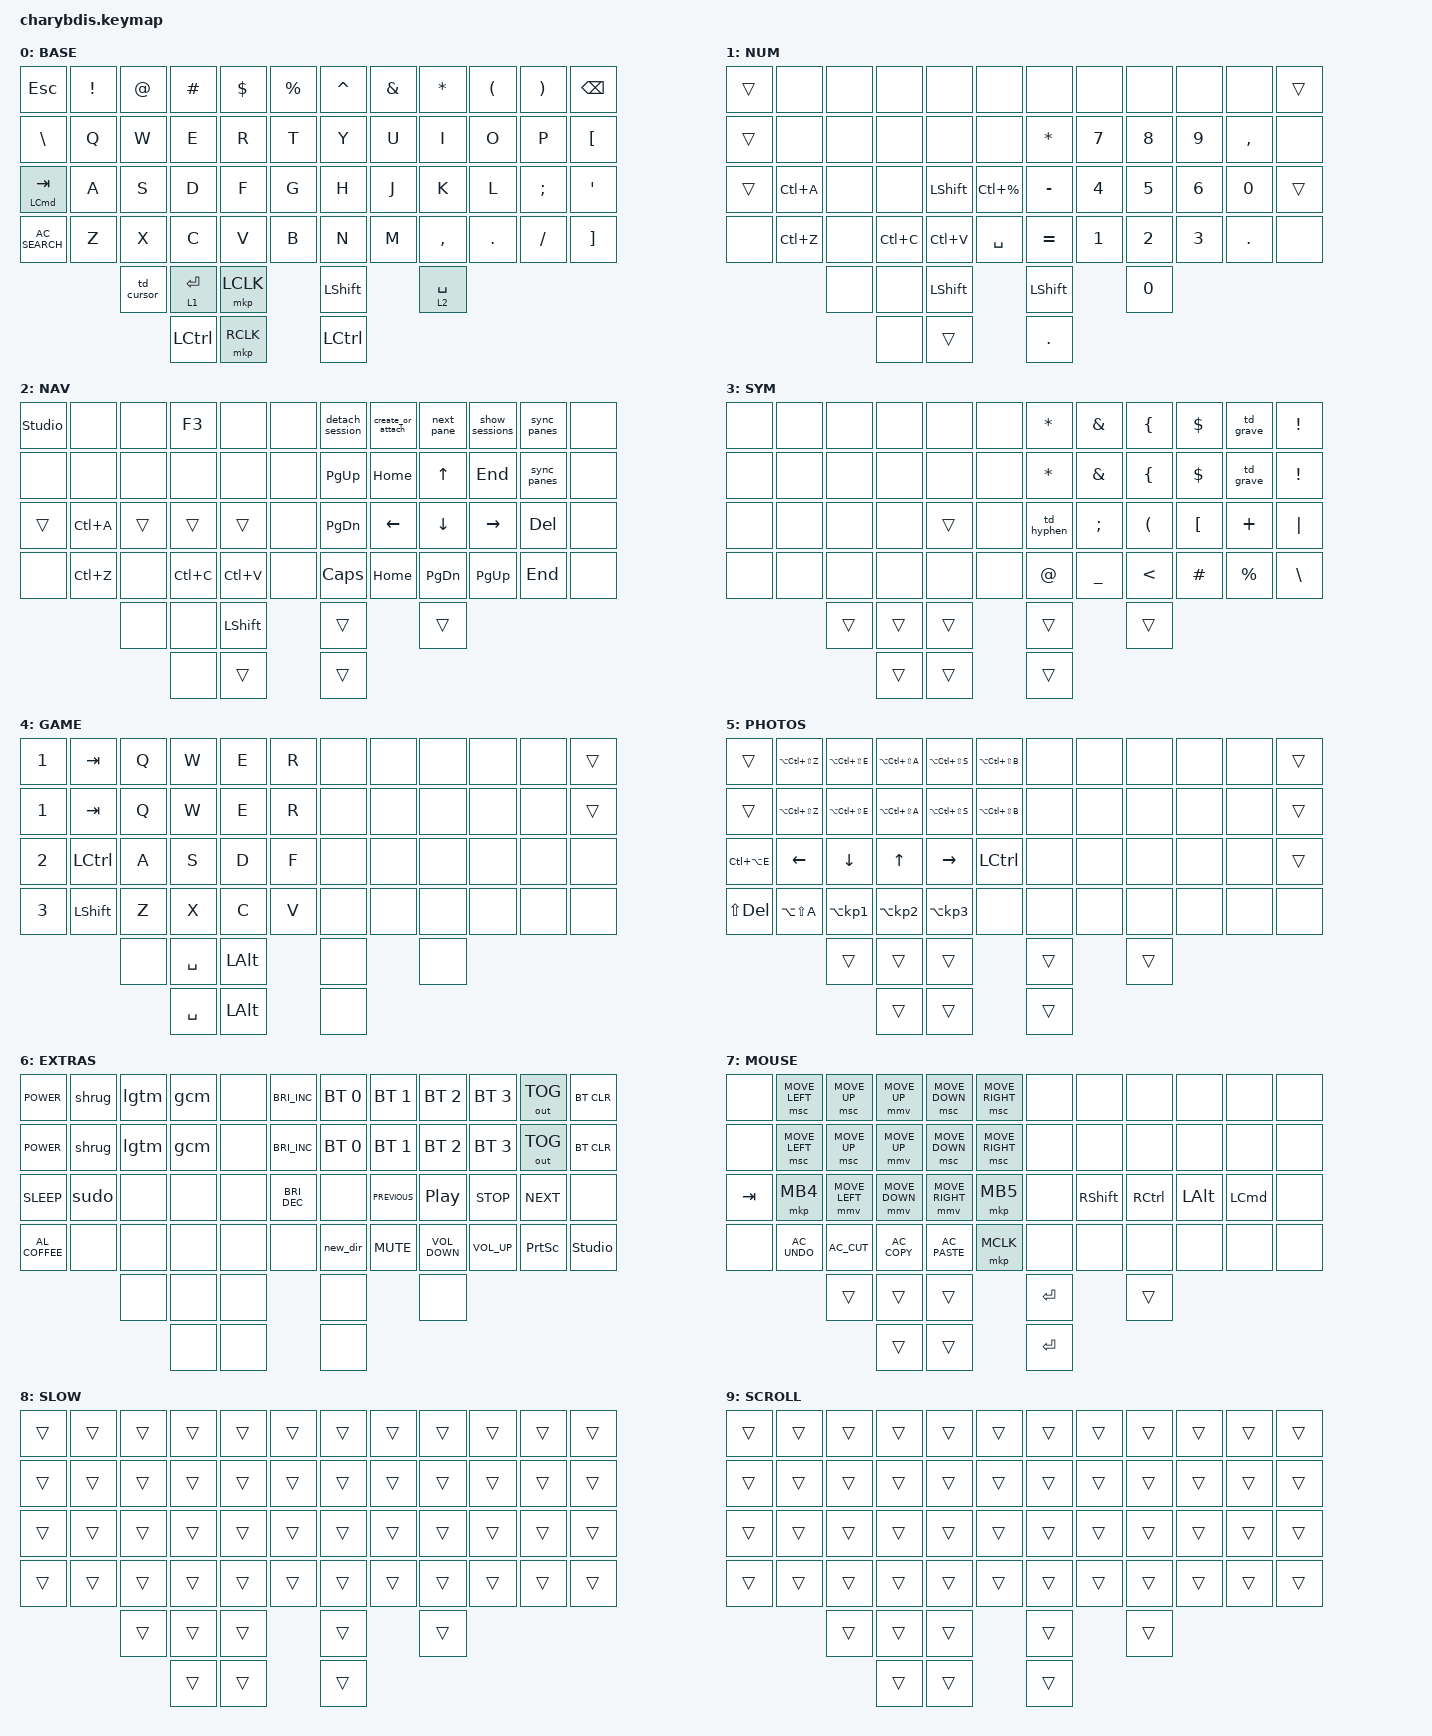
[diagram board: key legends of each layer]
#include <behaviors.dtsi>
#include <dt-bindings/zmk/bt.h>
#include <dt-bindings/zmk/keys.h>
#include <dt-bindings/zmk/mouse.h>
#include <dt-bindings/zmk/outputs.h>
#include <behaviors/mouse_keys.dtsi>
#include <dt-bindings/zmk/ext_power.h>
#include "macros.dtsi"
#include "behaviors.dtsi"
#include "combos.dtsi"

/ {
    /* input config for mouse move mode */
    trackball_listener {
        compatible = "zmk,input-behavior-listener";
        device = <&vtrackball>;
        layers = <0 2 7>;
        evt-type = <INPUT_EV_REL>;
        x-input-code = <INPUT_REL_X>;
        y-input-code = <INPUT_REL_Y>;
        scale-multiplier = <4>;
        scale-divisor = <5>;
        // bindings = <&ib_toggle_layer 7>;
    };

    /* input config for snipe mode */
    trackball_snipe_listener {
        compatible = "zmk,input-behavior-listener";   
        device = <&vtrackball>;
        layers = <8>;
        evt-type = <INPUT_EV_REL>;
        x-input-code = <INPUT_REL_X>;
        y-input-code = <INPUT_REL_Y>;
        scale-multiplier = <1>;
        scale-divisor = <2>;
    };

    /* input config for mouse scroll mode */
    trackball_scroll_listener {
        compatible = "zmk,input-behavior-listener";
        device = <&vtrackball>;
        layers = <9>;
        evt-type = <INPUT_EV_REL>;            
        y-input-code = <INPUT_REL_WHEEL>;
        y-invert;
        bindings = <&ib_wheel_scaler 1 8>;
    };

    /* define a resolution down scaler only for INPUT_REL_WHEEL */
    ib_wheel_scaler: ib_wheel_scaler {
        compatible = "zmk,input-behavior-scaler";
        #binding-cells = <2>;
        evt-type = <INPUT_EV_REL>;
        input-code = <INPUT_REL_WHEEL>;
        
    };

    /* adjust cooldown waiting period for mouse key layer after activated */
    ib_toggle_layer: ib_toggle_layer {
        compatible = "zmk,input-behavior-tog-layer";
        #binding-cells = <1>;
        time-to-live-ms = <750>;
    };
// ╭──────┬──────┬──────┬──────┬──────┬──────╮  ╭──────┬──────┬──────┬──────┬──────┬──────╮
//    00     01     02     03    04      05        06     07     08     09     10     11
// ├──────┼──────┼──────┼──────┼──────┼──────┤  ├──────┼──────┼──────┼──────┼──────┼──────┤
//    12     13     14     15    16      17        18     19     20     21     22     23
// ├──────┼──────┼──────┼──────┼──────┼──────┤  ├──────┼──────┼──────┼──────┼──────┼──────┤
//    24     25     26     27    28      29        30     31     32     33     34     35
// ├──────┼──────┼──────┼──────┼──────┼──────┤  ├──────┼──────┼──────┼──────┼──────┼──────┤
//    36     37     38     39    40      41        42     43     44     45     46     47
// ╰──────┴──────┴──────┼──────┼──────┼──────┤  ├──────┼──────┼──────┴──────┴──────┴──────╯
//                         48     49     50        53     54
//                       ──────┼──────┼──────┤  ├──────┼──────┼
//                                51     52        55
//                             ╰──────┴──────╯  ╰──────╯
// #define BASE    0
// #define NUM     1
// #define NAV     2
// #define SYM     3
// #define GAME    4
// #define PHOTOS  5
// #define EXTRAS  6
// #define MOUSE   7
// #define SLOW    8
// #define SCROLL  9

    keymap {
        compatible = "zmk,keymap";
        BASE {
            bindings = <
// ╭────────────────┬──────────────┬─────────────────────────────┬──────────────────────────────────┬──────────────────────┬────────╮  ╭────────────────┬─────────────────────────┬──────────────────────────────────────┬────────────────────────────────────┬────────────────────────┬──────────────╮
    &kp ESC            &kp EXCL        &kp AT                         &kp HASH                         &kp DOLLAR             &kp PERCENT &kp CARET         &kp AMPS                &kp STAR                                &kp LPAR                             &kp RPAR                 &kp BACKSPACE
// ├────────────────┼──────────────┼─────────────────────────────┼──────────────────────────────────┼──────────────────────┼────────┤  ├────────────────┼─────────────────────────┼──────────────────────────────────────┼────────────────────────────────────┼────────────────────────┼──────────────┤
    &kp BACKSLASH      &kp Q           &kp W                          &kp E                              &kp R                  &kp T       &kp Y             &kp U                   &kp I                                   &kp O                                &kp P                    &kp LEFT_BRACKET
// ├────────────────┼──────────────┼─────────────────────────────┼──────────────────────────────────┼──────────────────────┼────────┤  ├────────────────┼─────────────────────────┼──────────────────────────────────────┼────────────────────────────────────┼────────────────────────┼──────────────┤
    &hm_left LCMD TAB  &kp A         &kp S                            &kp D                             &kp F                   &kp G       &kp H             &kp J                   &kp K                                   &kp L                                &kp SEMICOLON            &kp SINGLE_QUOTE
// ├────────────────┼──────────────┼─────────────────────────────┼──────────────────────────────────┼──────────────────────┼────────┤  ├────────────────┼─────────────────────────┼──────────────────────────────────────┼────────────────────────────────────┼────────────────────────┼──────────────┤
    &kp C_AC_SEARCH    &kp Z           &kp X                          &kp C                              &kp V                  &kp B       &kp N             &kp M                   &kp COMMA                               &kp PERIOD                           &kp FSLH                 &kp RIGHT_BRACKET
// ╰────────────────┴──────────────┴─────────────────────────────┼──────────────────────────────────┼──────────────────────┼────────┤  ├────────────────┼─────────────────────────┼──────────────────────────────────────┴────────────────────────────────────┴────────────────────────┴──────────────╯
                                                                               &td_cursor    &lt 1 RETURN       &mkp LCLK                &kp LEFT_SHIFT      &lt 2 SPACE
                                                                                             &kp LCTRL          &mkp RCLK                &kp LEFT_CONTROL
                                                                          // ╰─────────────┴──────────────────┴────────╯               ╰────────────────┴──────────────╯
            >;
        };

        NUM {
            bindings = <
&trans   &none      &none  &none      &none          &none          &none      &none   &none   &none   &none       &trans
&trans   &none      &none  &none      &none          &none          &kp ASTRK  &kp N7  &kp N8  &kp N9  &kp COMMA   &none
&trans   &kp LC(A)  &none  &none      &kp LEFT_SHIFT &kp LC(PRCNT)  &kp MINUS  &kp N4  &kp N5  &kp N6  &kp N0      &trans
&none    &kp LC(Z)  &none  &kp LC(C)  &kp LC(V)      &kp SPACE      &kp EQUAL  &kp N1  &kp N2  &kp N3  &kp PERIOD  &none
                       &none  &none          &kp LEFT_SHIFT         &kp LEFT_SHIFT    &kp N0
                              &none          &trans                 &kp DOT
            >;
        };

        NAV {
            bindings = <

&studio_unlock  &none   &none   &kp F3  &none   &none     &detach_session  &create_or_attach  &next_pane        &show_sessions  &sync_panes       &none
&none           &none   &none   &none   &none   &none     &kp PG_UP        &kp HOME           &kp UP_ARROW      &kp END         &sync_panes       &none
&trans          &kp LC(A)  &trans  &trans  &trans  &none     &kp PAGE_DOWN    &kp LEFT_ARROW     &kp DOWN_ARROW    &kp RIGHT_ARROW &kp DELETE        &none
&none           &kp LC(Z)   &none   &kp LC(C)   &kp LC(V)   &none     &kp CAPSLOCK     &kp HOME           &kp PG_DN         &kp PG_UP       &kp END           &none
                                &none   &none   &kp LEFT_SHIFT    &trans   &trans
                                        &none   &trans    &trans
            >;
        };

        SYM {
            bindings = <
&none  &none  &none  &none  &none   &none      &kp ASTRK   &kp AMPS       &kp LEFT_BRACE &kp DLLR &td_grave &kp EXCL
&none  &none  &none  &none  &none   &none      &kp ASTRK   &kp AMPS       &kp LEFT_BRACE &kp DLLR &td_grave &kp EXCL
&none  &none  &none  &none  &trans  &none      &td_hyphen  &kp SEMICOLON  &kp LPAR       &kp LBKT &kp PLUS  &kp PIPE
&none  &none  &none  &none  &none   &none      &kp AT_SIGN &kp UNDERSCORE &kp LT         &kp HASH &kp PRCNT &kp BSLH
                   &trans  &trans  &trans      &trans      &trans
                            &trans  &trans      &trans
            >;
        };

        GAME {
            bindings = <
&kp N1  &kp TAB    &kp Q  &kp W   &kp E      &kp R           &none  &none  &none  &none  &none  &trans
&kp N1  &kp TAB    &kp Q  &kp W   &kp E      &kp R           &none  &none  &none  &none  &none  &trans
&kp N2  &kp LCTRL  &kp A  &kp S   &kp D      &kp F           &none  &none  &none  &none  &none  &none
&kp N3  &kp LSHFT  &kp Z  &kp X   &kp C      &kp V           &none  &none  &none  &none  &none  &none
                          &none   &kp SPACE  &kp LEFT_ALT    &none  &none
                                  &kp SPACE  &kp LEFT_ALT    &none
            >;
        };

        PHOTOS {
            bindings = <
&trans          &kp LA(LC(LS(Z)))  &kp LA(LC(LS(E)))  &kp LA(LC(LS(A)))  &kp LA(LC(LS(S)))  &kp LA(LC(LS(B)))    &none   &none   &none  &none  &none  &trans
&trans          &kp LA(LC(LS(Z)))  &kp LA(LC(LS(E)))  &kp LA(LC(LS(A)))  &kp LA(LC(LS(S)))  &kp LA(LC(LS(B)))    &none   &none   &none  &none  &none  &trans
&kp LC(LA(E))   &kp LEFT           &kp DOWN           &kp UP             &kp RIGHT          &kp LCTRL            &none   &none   &none  &none  &none  &trans
&kp LS(DELETE)  &kp LA(LS(A))      &kp LA(KP_N1)      &kp LA(KP_N2)      &kp LA(KP_N3)      &none                &none   &none   &none  &none  &none  &none
                                                      &trans             &trans             &trans               &trans  &trans
                                                                         &trans             &trans               &trans
            >;
        };

        EXTRAS {
            bindings = <
&kp C_POWER       &shrug  &lgtm     &gcm      &none  &kp C_BRIGHTNESS_INC    &bt BT_SEL 0  &bt BT_SEL 1    &bt BT_SEL 2       &bt BT_SEL 3  &out OUT_TOG     &bt BT_CLR
&kp C_POWER       &shrug  &lgtm     &gcm      &none  &kp C_BRIGHTNESS_INC    &bt BT_SEL 0  &bt BT_SEL 1    &bt BT_SEL 2       &bt BT_SEL 3  &out OUT_TOG     &bt BT_CLR
&kp C_SLEEP       &sudo   &none     &none     &none  &kp C_BRIGHTNESS_DEC    &none         &kp C_PREVIOUS  &kp C_PLAY_PAUSE   &kp C_STOP    &kp C_NEXT       &none
&kp C_AL_COFFEE   &none   &none     &none     &none  &none                   &new_dir      &kp K_MUTE      &kp C_VOLUME_DOWN  &kp C_VOLUME_UP   &kp PRINTSCREEN  &studio_unlock
                                    &none     &none  &none                   &none         &none
                                              &none  &none                   &none
            >;
        };

        MOUSE {
            bindings = <
&none    &msc MOVE_LEFT  &msc MOVE_UP    &mmv MOVE_UP    &msc MOVE_DOWN   &msc MOVE_RIGHT    &none  &none            &none      &none         &none          &none
&none    &msc MOVE_LEFT  &msc MOVE_UP    &mmv MOVE_UP    &msc MOVE_DOWN   &msc MOVE_RIGHT    &none  &none            &none      &none         &none          &none
&kp TAB  &mkp MB4        &mmv MOVE_LEFT  &mmv MOVE_DOWN  &mmv MOVE_RIGHT  &mkp MB5           &none  &kp RIGHT_SHIFT  &kp RCTRL  &kp LEFT_ALT  &kp LCMD  &none
&none    &kp C_AC_UNDO   &kp C_AC_CUT    &kp C_AC_COPY   &kp C_AC_PASTE   &mkp MCLK          &none  &none            &none      &none         &none          &none
                                         &trans          &trans           &trans             &kp RETURN              &trans
                                                         &trans           &trans             &kp RETURN
            >;
        };

        SLOW {
            bindings = <
&trans    &trans    &trans    &trans    &trans    &trans    &trans    &trans    &trans    &trans    &trans    &trans
&trans    &trans    &trans    &trans    &trans    &trans    &trans    &trans    &trans    &trans    &trans    &trans
&trans    &trans    &trans    &trans    &trans    &trans    &trans    &trans    &trans    &trans    &trans    &trans
&trans    &trans    &trans    &trans    &trans    &trans    &trans    &trans    &trans    &trans    &trans    &trans
                              &trans    &trans    &trans    &trans    &trans
                                        &trans    &trans    &trans
            >;
        };

        SCROLL {
            bindings = <
&trans    &trans    &trans    &trans    &trans    &trans    &trans    &trans    &trans    &trans    &trans    &trans
&trans    &trans    &trans    &trans    &trans    &trans    &trans    &trans    &trans    &trans    &trans    &trans
&trans    &trans    &trans    &trans    &trans    &trans    &trans    &trans    &trans    &trans    &trans    &trans
&trans    &trans    &trans    &trans    &trans    &trans    &trans    &trans    &trans    &trans    &trans    &trans
                              &trans    &trans    &trans    &trans    &trans
                                        &trans    &trans    &trans
            >;
        };
    };
};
